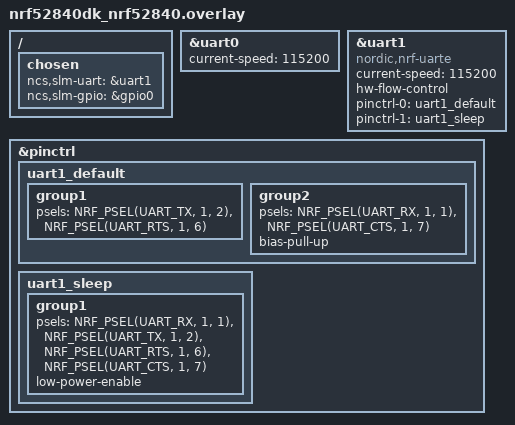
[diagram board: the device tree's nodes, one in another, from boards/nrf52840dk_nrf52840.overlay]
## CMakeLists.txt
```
#
# Copyright (c) 2025 Nordic Semiconductor ASA
#
# SPDX-License-Identifier: LicenseRef-Nordic-5-Clause
#

cmake_minimum_required(VERSION 3.20.0)

find_package(Zephyr REQUIRED HINTS $ENV{ZEPHYR_BASE})
project(metering)

target_sources(app PRIVATE src/main.c)
```

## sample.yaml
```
sample:
  description: Metering sample
  name: metering
tests:
  sample.cellular.metering:
    sysbuild: true
    build_only: true
    platform_allow:
      - nrf52840dk/nrf52840
      - nrf5340dk/nrf5340/cpuapp
      - nrf7002dk/nrf5340/cpuapp
    integration_platforms:
      - nrf52840dk/nrf52840
      - nrf5340dk/nrf5340/cpuapp
      - nrf7002dk/nrf5340/cpuapp
    tags:
      - ci_build
      - sysbuild
      - ci_samples_cellular
```

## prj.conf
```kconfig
#
# Copyright (c) 2025 Nordic Semiconductor ASA
#
# SPDX-License-Identifier: LicenseRef-Nordic-5-Clause
#

CONFIG_STACK_SENTINEL=y
CONFIG_MAIN_STACK_SIZE=4096
CONFIG_HEAP_MEM_POOL_SIZE=8192
CONFIG_SYSTEM_WORKQUEUE_STACK_SIZE=2048

CONFIG_LOG=y
CONFIG_LOG_BACKEND_UART=y
CONFIG_CONSOLE=y
CONFIG_UART_CONSOLE=y
CONFIG_SHELL=y
CONFIG_SHELL_WILDCARD=n
CONFIG_SHELL_ARGC_MAX=40
CONFIG_SHELL_CMD_BUFF_SIZE=1024
CONFIG_SHELL_STACK_SIZE=2048
CONFIG_SHELL_LOG_BACKEND=n

CONFIG_SERIAL=y
CONFIG_UART_ASYNC_API=y

CONFIG_MODEM_SLM=y
CONFIG_MODEM_SLM_SHELL=y
#CONFIG_MODEM_SLM_LOG_LEVEL_DBG=y

CONFIG_ASSERT=y
```

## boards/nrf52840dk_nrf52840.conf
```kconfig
#
# Copyright (c) 2025 Nordic Semiconductor ASA
#
# SPDX-License-Identifier: LicenseRef-Nordic-5-Clause
#

# Configuration file for nRF52840DK.
# This file is merged with prj.conf in the application folder, and options
# set here will take precedence if they are present in both files.

CONFIG_NRFX_UARTE1=y
CONFIG_UART_1_INTERRUPT_DRIVEN=n
CONFIG_UART_1_ASYNC=y
CONFIG_MODEM_SLM_POWER_PIN=11
CONFIG_MODEM_SLM_INDICATE_PIN=13
```

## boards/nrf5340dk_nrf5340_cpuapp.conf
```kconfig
#
# Copyright (c) 2025 Nordic Semiconductor ASA
#
# SPDX-License-Identifier: LicenseRef-Nordic-5-Clause
#

# Configuration file for nRF5340DK.
# This file is merged with prj.conf in the application folder, and options
# set here will take precedence if they are present in both files.

CONFIG_NRFX_UARTE2=y
CONFIG_UART_2_INTERRUPT_DRIVEN=n
CONFIG_UART_2_ASYNC=y
CONFIG_MODEM_SLM_POWER_PIN=23
CONFIG_MODEM_SLM_INDICATE_PIN=28
```

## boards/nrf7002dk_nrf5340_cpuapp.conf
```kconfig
#
# Copyright (c) 2025 Nordic Semiconductor ASA
#
# SPDX-License-Identifier: LicenseRef-Nordic-5-Clause
#

# Configuration file for nRF7002DK.
# This file is merged with prj.conf in the application folder, and options
# set here will take precedence if they are present in both files.

CONFIG_NRFX_UARTE2=y
CONFIG_UART_2_INTERRUPT_DRIVEN=n
CONFIG_UART_2_ASYNC=y
CONFIG_MODEM_SLM_POWER_PIN=30
CONFIG_MODEM_SLM_INDICATE_PIN=31
```

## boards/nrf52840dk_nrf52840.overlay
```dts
/*
 * Copyright (c) 2025 Nordic Semiconductor ASA
 *
 * SPDX-License-Identifier: LicenseRef-Nordic-5-Clause
 */

/ {
	chosen {
		ncs,slm-uart = &uart1;
		ncs,slm-gpio = &gpio0;
	};
};

/* Shell UART */
&uart0 {
	current-speed = <115200>;
	status = "okay";
};

/* SLM Shell <-> SLM UART */
&uart1 {
	compatible = "nordic,nrf-uarte";
	current-speed = <115200>;
	status = "okay";
	hw-flow-control;

	pinctrl-0 = <&uart1_default>;
	pinctrl-1 = <&uart1_sleep>;
	pinctrl-names = "default", "sleep";
};

&pinctrl {
	uart1_default: uart1_default {
		group1 {
			psels = <NRF_PSEL(UART_TX, 1, 2)>,
				<NRF_PSEL(UART_RTS, 1, 6)>;
		};
		group2 {
			psels = <NRF_PSEL(UART_RX, 1, 1)>,
				<NRF_PSEL(UART_CTS, 1, 7)>;
			bias-pull-up;
		};
	};

	uart1_sleep: uart1_sleep {
		group1 {
			psels = <NRF_PSEL(UART_RX, 1, 1)>,
				<NRF_PSEL(UART_TX, 1, 2)>,
				<NRF_PSEL(UART_RTS, 1, 6)>,
				<NRF_PSEL(UART_CTS, 1, 7)>;
			low-power-enable;
		};
	};
};
```

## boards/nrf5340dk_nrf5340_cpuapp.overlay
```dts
/*
 * Copyright (c) 2025 Nordic Semiconductor ASA
 *
 * SPDX-License-Identifier: LicenseRef-Nordic-5-Clause
 */

/ {
	chosen {
		ncs,slm-uart = &uart2;
		ncs,slm-gpio = &gpio0;
	};
};

/* Shell UART */
&uart0 {
	current-speed = <115200>;
	status = "okay";
};

/* SLM Shell <-> SLM UART */
&uart2 {
	compatible = "nordic,nrf-uarte";
	current-speed = <115200>;
	status = "okay";
	hw-flow-control;
	pinctrl-0 = <&uart2_default>;
	pinctrl-1 = <&uart2_sleep>;
	pinctrl-names = "default", "sleep";
};

&pinctrl {
	uart2_default: uart2_default {
		group1 {
			psels = <NRF_PSEL(UART_TX, 1, 4)>,
				<NRF_PSEL(UART_RTS, 1, 6)>;
		};
		group2 {
			psels = <NRF_PSEL(UART_RX, 1, 5)>,
				<NRF_PSEL(UART_CTS, 1, 7)>;
			bias-pull-up;
		};
	};

	uart2_sleep: uart2_sleep {
		group1 {
			psels = <NRF_PSEL(UART_TX, 1, 4)>,
				<NRF_PSEL(UART_RX, 1, 5)>,
				<NRF_PSEL(UART_RTS, 1, 6)>,
				<NRF_PSEL(UART_CTS, 1, 7)>;
			low-power-enable;
		};
	};
};
```

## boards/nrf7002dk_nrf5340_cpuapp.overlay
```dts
/*
 * Copyright (c) 2025 Nordic Semiconductor ASA
 *
 * SPDX-License-Identifier: LicenseRef-Nordic-5-Clause
 */

/ {
	chosen {
		ncs,slm-uart = &uart2;
		ncs,slm-gpio = &gpio0;
	};
};

/* Shell UART */
&uart0 {
	current-speed = <115200>;
	status = "okay";
};

/* SLM Shell <-> SLM UART */
&uart2 {
	compatible = "nordic,nrf-uarte";
	current-speed = <115200>;
	status = "okay";
	hw-flow-control;

	pinctrl-0 = <&uart2_default>;
	pinctrl-1 = <&uart2_sleep>;
	pinctrl-names = "default", "sleep";
};

&pinctrl {
	uart2_default: uart2_default {
		group1 {
			psels = <NRF_PSEL(UART_TX, 1, 4)>,
				<NRF_PSEL(UART_RTS, 1, 6)>;

		};
		group2 {
			psels = <NRF_PSEL(UART_RX, 1, 5)>,
				<NRF_PSEL(UART_CTS, 1, 7)>;
			bias-pull-up;
		};
	};

	uart2_sleep: uart2_sleep {
		group1 {
			psels = <NRF_PSEL(UART_TX, 1, 4)>,
				<NRF_PSEL(UART_RX, 1, 5)>,
				<NRF_PSEL(UART_RTS, 1, 6)>,
				<NRF_PSEL(UART_CTS, 1, 7)>;
			low-power-enable;
		};
	};
};
```

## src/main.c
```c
/*
 * Copyright (c) 2025 Nordic Semiconductor ASA
 *
 * SPDX-License-Identifier: LicenseRef-Nordic-5-Clause
 */

#include <stdlib.h>
#include <modem/modem_slm.h>
#include <zephyr/logging/log.h>

LOG_MODULE_REGISTER(app, CONFIG_LOG_DEFAULT_LEVEL);

SLM_MONITOR(network, "\r\n+CEREG:", cereg_monitor);

#define SLM_AT_CMD_TIMEOUT 10

static void cereg_monitor(const char *notif)
{
	int status = atoi(notif + strlen("\r\n+CEREG: "));

	if (status == 1 || status == 5) {
		LOG_INF("LTE connected");
	}
}

void metering_data_indication(const uint8_t *data, size_t datalen)
{
	LOG_DBG("Data received (len=%d): %.*s", datalen, datalen, (const char *)data);
}

void metering_indication_handler(void)
{
	int err;

	LOG_INF("SLM indicate pin triggered");
	err = modem_slm_power_pin_toggle();
	if (err) {
		LOG_ERR("Failed to toggle power pin");
	}
}

static int metering_init(void)
{
	int err;

	err = modem_slm_init(metering_data_indication);
	if (err) {
		LOG_ERR("Failed to initialize SLM: %d", err);
	}

	err = modem_slm_register_ind(metering_indication_handler, true);
	if (err) {
		LOG_ERR("Failed to register indication: %d", err);
	}

	k_sleep(K_SECONDS(1));

	LOG_INF("Register to network");

	err = modem_slm_send_cmd("AT+CEREG=5", SLM_AT_CMD_TIMEOUT);
	if (err != 0) {
		LOG_ERR("Failed to set CEREG: %d", err);
	}

	err = modem_slm_send_cmd("AT%REDMOB=1", SLM_AT_CMD_TIMEOUT);
	if (err != 0) {
		LOG_ERR("Failed to set REDMOB: %d", err);
	}
	err = modem_slm_send_cmd("AT%XMODEMSLEEP=1,5000,10240", SLM_AT_CMD_TIMEOUT);
	if (err != 0) {
		LOG_ERR("Failed to set CEREG: %d", err);
	}
	err = modem_slm_send_cmd("AT%XTIME=1", SLM_AT_CMD_TIMEOUT);
	if (err != 0) {
		LOG_ERR("Failed to set XTIME: %d", err);
	}
	err = modem_slm_send_cmd("AT+CFUN=1", SLM_AT_CMD_TIMEOUT);
	if (err != 0) {
		LOG_ERR("Failed to set CFUN: %d", err);
	}

	LOG_INF("Check time");
	err = modem_slm_send_cmd("AT+CCLK?", SLM_AT_CMD_TIMEOUT);
	if (err != 0) {
		LOG_ERR("Failed to set CCLK: %d", err);
	}

	return 0;
}

static int edrx(void)
{
	int err;

	LOG_INF("Set eDRX");
	err = modem_slm_send_cmd("AT+CPSMS=0", SLM_AT_CMD_TIMEOUT);
	if (err != 0) {
		LOG_ERR("Failed to set CPSMS: %d", err);
	}
	err = modem_slm_send_cmd("AT+CEDRXS=1,4,\"0100\"", SLM_AT_CMD_TIMEOUT);
	if (err != 0) {
		LOG_ERR("Failed to set CEDRXS: %d", err);
	}
	err = modem_slm_send_cmd("AT%XPTW=4,\"0111\"", SLM_AT_CMD_TIMEOUT);
	if (err != 0) {
		LOG_ERR("Failed to set XPTW: %d", err);
	}

	return 0;
}

static int psm(void)
{
	int err;

	LOG_INF("Set PSM");
	err = modem_slm_send_cmd("AT+CEDRXS=0", SLM_AT_CMD_TIMEOUT);
	if (err != 0) {
		LOG_ERR("Failed to set CEDRXS: %d", err);
	}
	err = modem_slm_send_cmd("AT+CPSMS=1,\"\",\"\",\"00000010\",\"00000010\"", SLM_AT_CMD_TIMEOUT);
	if (err != 0) {
		LOG_ERR("Failed to set CPSMS: %d", err);
	}

	return 0;
}

static int ping(void)
{
	int err;

	err = modem_slm_send_cmd("slm AT#XPING=\"8.8.8.8\",10,1000,5", SLM_AT_CMD_TIMEOUT);
	if (err < 0) {
		LOG_ERR("Failed to perform XPING: %d", err);
	}

	return 0;
}

int main(void)
{
	LOG_INF("SLM Shell starts on %s", CONFIG_BOARD);

	metering_init();
	k_sleep(K_SECONDS(1));

	edrx();
	k_sleep(K_SECONDS(1));

	ping();

	return 0;
}
```
